# dsPIC33FJ64GS606 register map
Vendor: Microchip; Series: dsPIC33FJ64GS; File version: 1.4.228
Registers are 16-bit, read-write, no defined reset value unless marked. A register's access mark holds for its fields unless they carry their own. Offsets are from the block's base; [hi:lo] are bit positions; {n}, {i} and the like mark numbered series.

## INTERRUPT — INTERRUPT peripheral registers
Base 0x00000080
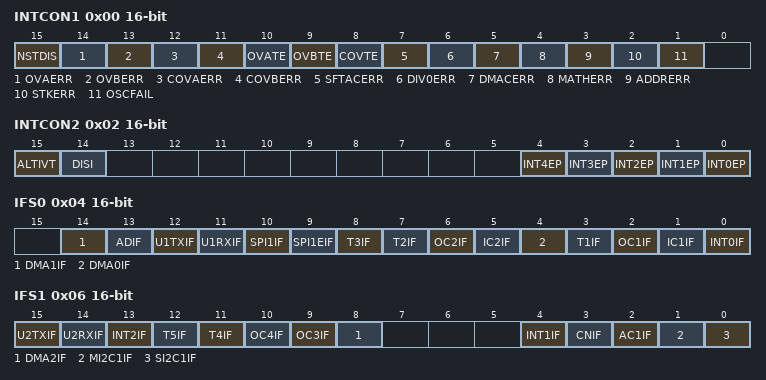
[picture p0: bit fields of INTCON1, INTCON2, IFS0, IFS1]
0x00 INTCON1
  [15] NSTDIS — INTCON1 field NSTDIS
  [14] OVAERR — INTCON1 field OVAERR
  [13] OVBERR — INTCON1 field OVBERR
  [12] COVAERR — INTCON1 field COVAERR
  [11] COVBERR — INTCON1 field COVBERR
  [10] OVATE — INTCON1 field OVATE
  [9] OVBTE — INTCON1 field OVBTE
  [8] COVTE — INTCON1 field COVTE
  [7] SFTACERR — INTCON1 field SFTACERR
  [6] DIV0ERR — INTCON1 field DIV0ERR
  [5] DMACERR — INTCON1 field DMACERR
  [4] MATHERR — INTCON1 field MATHERR
  [3] ADDRERR — INTCON1 field ADDRERR
  [2] STKERR — INTCON1 field STKERR
  [1] OSCFAIL — INTCON1 field OSCFAIL
0x02 INTCON2
  [15] ALTIVT — INTCON2 field ALTIVT
  [14] DISI — INTCON2 field DISI
  [n] INT{n}EP (n=0..4) — INTCON2 field INT{n}EP
0x04 IFS0
  [14] DMA1IF — IFS0 field DMA1IF
  [13] ADIF — IFS0 field ADIF
  [12] U1TXIF — IFS0 field U1TXIF
  [11] U1RXIF — IFS0 field U1RXIF
  [10] SPI1IF — IFS0 field SPI1IF
  [9] SPI1EIF — IFS0 field SPI1EIF
  [8] T3IF — IFS0 field T3IF
  [7] T2IF — IFS0 field T2IF
  [6] OC2IF — IFS0 field OC2IF
  [5] IC2IF — IFS0 field IC2IF
  [4] DMA0IF — IFS0 field DMA0IF
  [3] T1IF — IFS0 field T1IF
  [2] OC1IF — IFS0 field OC1IF
  [1] IC1IF — IFS0 field IC1IF
  [0] INT0IF — IFS0 field INT0IF
0x06 IFS1
  [15] U2TXIF — IFS1 field U2TXIF
  [14] U2RXIF — IFS1 field U2RXIF
  [13] INT2IF — IFS1 field INT2IF
  [12] T5IF — IFS1 field T5IF
  [11] T4IF — IFS1 field T4IF
  [10] OC4IF — IFS1 field OC4IF
  [9] OC3IF — IFS1 field OC3IF
  [8] DMA2IF — IFS1 field DMA2IF
  [4] INT1IF — IFS1 field INT1IF
  [3] CNIF — IFS1 field CNIF
  [2] AC1IF — IFS1 field AC1IF
  [1] MI2C1IF — IFS1 field MI2C1IF
  [0] SI2C1IF — IFS1 field SI2C1IF
0x08 IFS2
  [6] IC4IF — IFS2 field IC4IF
  [5] IC3IF — IFS2 field IC3IF
  [4] DMA3IF — IFS2 field DMA3IF
  [3] C1IF — IFS2 field C1IF
  [2] C1EIF — IFS2 field C1EIF
  [2] C1RXIF — IFS2 field C1RXIF
  [1] SPI2IF — IFS2 field SPI2IF
  [0] SPI2EIF — IFS2 field SPI2EIF
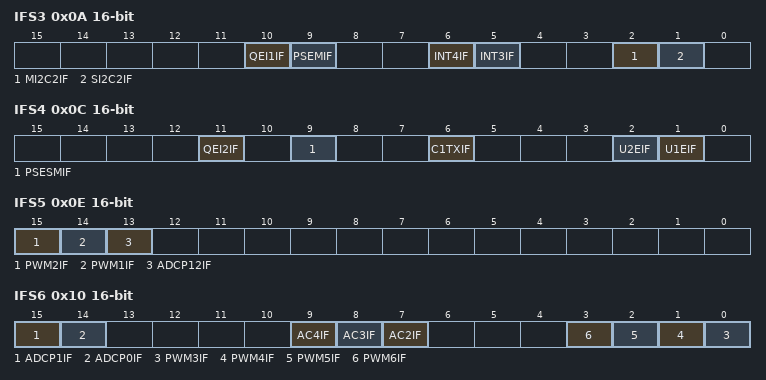
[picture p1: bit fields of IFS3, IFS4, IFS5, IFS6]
0x0A IFS3
  [10] QEI1IF — IFS3 field QEI1IF
  [9] PSEMIF — IFS3 field PSEMIF
  [6] INT4IF — IFS3 field INT4IF
  [5] INT3IF — IFS3 field INT3IF
  [2] MI2C2IF — IFS3 field MI2C2IF
  [1] SI2C2IF — IFS3 field SI2C2IF
0x0C IFS4
  [11] QEI2IF — IFS4 field QEI2IF
  [9] PSESMIF — IFS4 field PSESMIF
  [6] C1TXIF — IFS4 field C1TXIF
  [2] U2EIF — IFS4 field U2EIF
  [1] U1EIF — IFS4 field U1EIF
0x0E IFS5
  [15] PWM2IF — IFS5 field PWM2IF
  [14] PWM1IF — IFS5 field PWM1IF
  [13] ADCP12IF — IFS5 field ADCP12IF
0x10 IFS6
  [15] ADCP1IF — IFS6 field ADCP1IF
  [14] ADCP0IF — IFS6 field ADCP0IF
  [9] AC4IF — IFS6 field AC4IF
  [8] AC3IF — IFS6 field AC3IF
  [7] AC2IF — IFS6 field AC2IF
  [n-3] PWM{n}IF (n=3..6) — IFS6 field PWM{n}IF
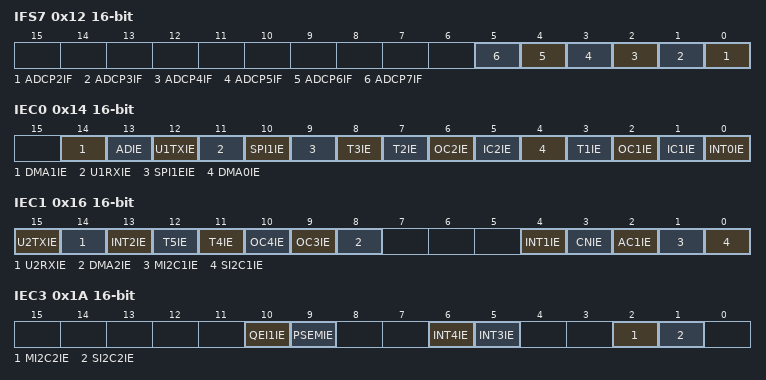
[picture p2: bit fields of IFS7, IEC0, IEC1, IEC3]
0x12 IFS7
  [n-2] ADCP{n}IF (n=2..7) — IFS7 field ADCP{n}IF
0x14 IEC0
  [14] DMA1IE — IEC0 field DMA1IE
  [13] ADIE — IEC0 field ADIE
  [12] U1TXIE — IEC0 field U1TXIE
  [11] U1RXIE — IEC0 field U1RXIE
  [10] SPI1IE — IEC0 field SPI1IE
  [9] SPI1EIE — IEC0 field SPI1EIE
  [8] T3IE — IEC0 field T3IE
  [7] T2IE — IEC0 field T2IE
  [6] OC2IE — IEC0 field OC2IE
  [5] IC2IE — IEC0 field IC2IE
  [4] DMA0IE — IEC0 field DMA0IE
  [3] T1IE — IEC0 field T1IE
  [2] OC1IE — IEC0 field OC1IE
  [1] IC1IE — IEC0 field IC1IE
  [0] INT0IE — IEC0 field INT0IE
0x16 IEC1
  [15] U2TXIE — IEC1 field U2TXIE
  [14] U2RXIE — IEC1 field U2RXIE
  [13] INT2IE — IEC1 field INT2IE
  [12] T5IE — IEC1 field T5IE
  [11] T4IE — IEC1 field T4IE
  [10] OC4IE — IEC1 field OC4IE
  [9] OC3IE — IEC1 field OC3IE
  [8] DMA2IE — IEC1 field DMA2IE
  [4] INT1IE — IEC1 field INT1IE
  [3] CNIE — IEC1 field CNIE
  [2] AC1IE — IEC1 field AC1IE
  [1] MI2C1IE — IEC1 field MI2C1IE
  [0] SI2C1IE — IEC1 field SI2C1IE
0x18 IEC2
  [6] IC4IE — IEC2 field IC4IE
  [5] IC3IE — IEC2 field IC3IE
  [4] DMA3IE — IEC2 field DMA3IE
  [3] C1IE — IEC2 field C1IE
  [2] C1EIE — IEC2 field C1EIE
  [2] C1RXIE — IEC2 field C1RXIE
  [1] SPI2IE — IEC2 field SPI2IE
  [0] SPI2EIE — IEC2 field SPI2EIE
0x1A IEC3
  [10] QEI1IE — IEC3 field QEI1IE
  [9] PSEMIE — IEC3 field PSEMIE
  [6] INT4IE — IEC3 field INT4IE
  [5] INT3IE — IEC3 field INT3IE
  [2] MI2C2IE — IEC3 field MI2C2IE
  [1] SI2C2IE — IEC3 field SI2C2IE
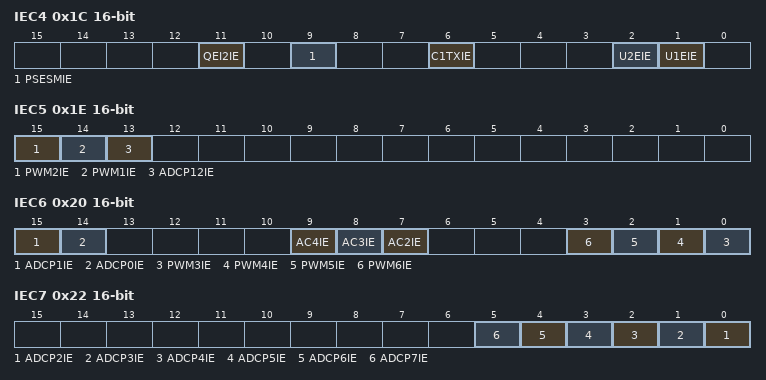
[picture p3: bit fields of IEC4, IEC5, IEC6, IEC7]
0x1C IEC4
  [11] QEI2IE — IEC4 field QEI2IE
  [9] PSESMIE — IEC4 field PSESMIE
  [6] C1TXIE — IEC4 field C1TXIE
  [2] U2EIE — IEC4 field U2EIE
  [1] U1EIE — IEC4 field U1EIE
0x1E IEC5
  [15] PWM2IE — IEC5 field PWM2IE
  [14] PWM1IE — IEC5 field PWM1IE
  [13] ADCP12IE — IEC5 field ADCP12IE
0x20 IEC6
  [15] ADCP1IE — IEC6 field ADCP1IE
  [14] ADCP0IE — IEC6 field ADCP0IE
  [9] AC4IE — IEC6 field AC4IE
  [8] AC3IE — IEC6 field AC3IE
  [7] AC2IE — IEC6 field AC2IE
  [n-3] PWM{n}IE (n=3..6) — IEC6 field PWM{n}IE
0x22 IEC7
  [n-2] ADCP{n}IE (n=2..7) — IEC7 field ADCP{n}IE
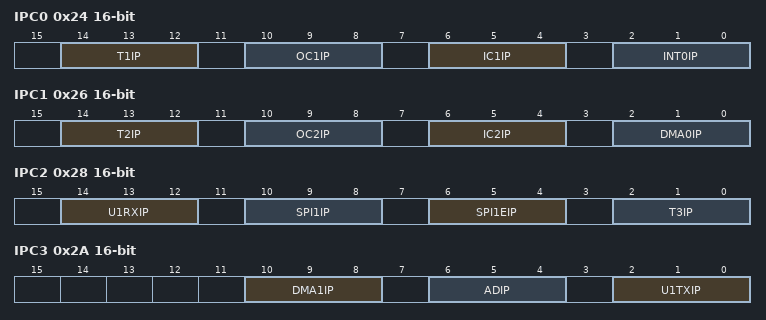
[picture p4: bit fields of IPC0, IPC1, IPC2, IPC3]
0x24 IPC0
  [14:12] T1IP — IPC0 field T1IP
  [10:8] OC1IP — IPC0 field OC1IP
  [6:4] IC1IP — IPC0 field IC1IP
  [2:0] INT0IP — IPC0 field INT0IP
0x26 IPC1
  [14:12] T2IP — IPC1 field T2IP
  [10:8] OC2IP — IPC1 field OC2IP
  [6:4] IC2IP — IPC1 field IC2IP
  [2:0] DMA0IP — IPC1 field DMA0IP
0x28 IPC2
  [14:12] U1RXIP — IPC2 field U1RXIP
  [10:8] SPI1IP — IPC2 field SPI1IP
  [6:4] SPI1EIP — IPC2 field SPI1EIP
  [2:0] T3IP — IPC2 field T3IP
0x2A IPC3
  [10:8] DMA1IP — IPC3 field DMA1IP
  [6:4] ADIP — IPC3 field ADIP
  [2:0] U1TXIP — IPC3 field U1TXIP
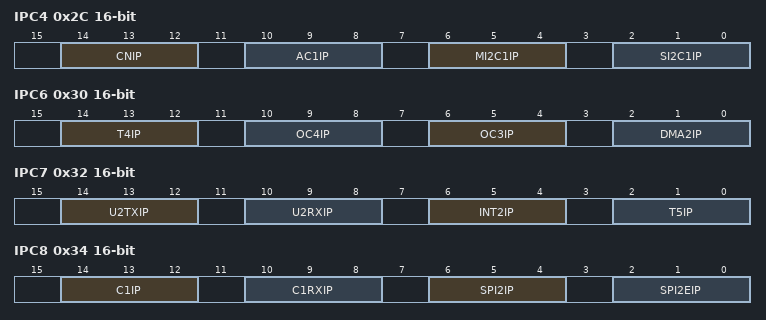
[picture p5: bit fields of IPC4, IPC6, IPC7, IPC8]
0x2C IPC4
  [14:12] CNIP — IPC4 field CNIP
  [10:8] AC1IP — IPC4 field AC1IP
  [6:4] MI2C1IP — IPC4 field MI2C1IP
  [2:0] SI2C1IP — IPC4 field SI2C1IP
0x2E IPC5
  [2:0] INT1IP — IPC5 field INT1IP
0x30 IPC6
  [14:12] T4IP — IPC6 field T4IP
  [10:8] OC4IP — IPC6 field OC4IP
  [6:4] OC3IP — IPC6 field OC3IP
  [2:0] DMA2IP — IPC6 field DMA2IP
0x32 IPC7
  [14:12] U2TXIP — IPC7 field U2TXIP
  [10:8] U2RXIP — IPC7 field U2RXIP
  [6:4] INT2IP — IPC7 field INT2IP
  [2:0] T5IP — IPC7 field T5IP
0x34 IPC8
  [14:12] C1IP — IPC8 field C1IP
  [10:8] C1RXIP — IPC8 field C1RXIP
  [6:4] SPI2IP — IPC8 field SPI2IP
  [2:0] SPI2EIP — IPC8 field SPI2EIP
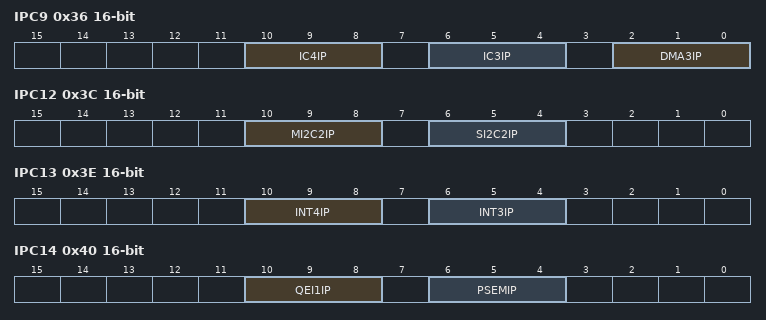
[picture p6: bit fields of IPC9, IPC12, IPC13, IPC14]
0x36 IPC9
  [10:8] IC4IP — IPC9 field IC4IP
  [6:4] IC3IP — IPC9 field IC3IP
  [2:0] DMA3IP — IPC9 field DMA3IP
0x3C IPC12
  [10:8] MI2C2IP — IPC12 field MI2C2IP
  [6:4] SI2C2IP — IPC12 field SI2C2IP
0x3E IPC13
  [10:8] INT4IP — IPC13 field INT4IP
  [6:4] INT3IP — IPC13 field INT3IP
0x40 IPC14
  [10:8] QEI1IP — IPC14 field QEI1IP
  [6:4] PSEMIP — IPC14 field PSEMIP
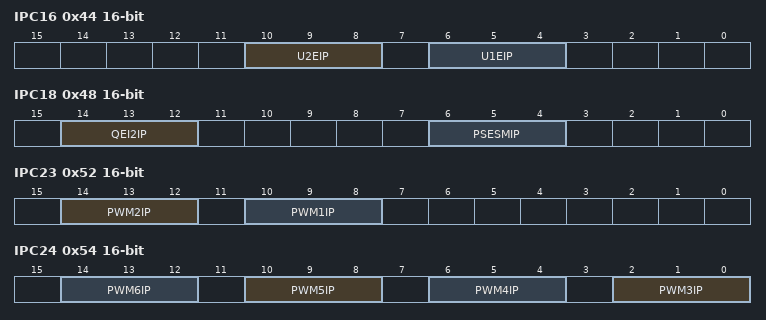
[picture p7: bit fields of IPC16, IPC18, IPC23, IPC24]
0x44 IPC16
  [10:8] U2EIP — IPC16 field U2EIP
  [6:4] U1EIP — IPC16 field U1EIP
0x46 IPC17
  [10:8] C1TXIP — IPC17 field C1TXIP
0x48 IPC18
  [14:12] QEI2IP — IPC18 field QEI2IP
  [6:4] PSESMIP — IPC18 field PSESMIP
0x4E IPC21
  [6:4] ADCP12IP — IPC21 field ADCP12IP
0x52 IPC23
  [14:12] PWM2IP — IPC23 field PWM2IP
  [10:8] PWM1IP — IPC23 field PWM1IP
0x54 IPC24
  [4n-10:4n-12] PWM{n}IP (n=3..6) — IPC24 field PWM{n}IP
0x56 IPC25
  [14:12] AC2IP — IPC25 field AC2IP
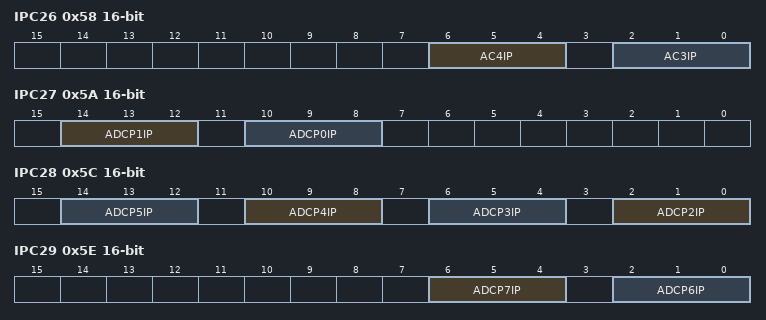
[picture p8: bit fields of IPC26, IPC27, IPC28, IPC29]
0x58 IPC26
  [6:4] AC4IP — IPC26 field AC4IP
  [2:0] AC3IP — IPC26 field AC3IP
0x5A IPC27
  [14:12] ADCP1IP — IPC27 field ADCP1IP
  [10:8] ADCP0IP — IPC27 field ADCP0IP
0x5C IPC28
  [4n-6:4n-8] ADCP{n}IP (n=2..5) — IPC28 field ADCP{n}IP
0x5E IPC29
  [6:4] ADCP7IP — IPC29 field ADCP7IP
  [2:0] ADCP6IP — IPC29 field ADCP6IP
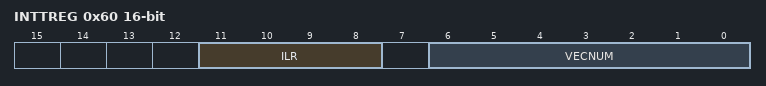
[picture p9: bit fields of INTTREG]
0x60 INTTREG
  [11:8] ILR — INTTREG field ILR
  [6:0] VECNUM — INTTREG field VECNUM
